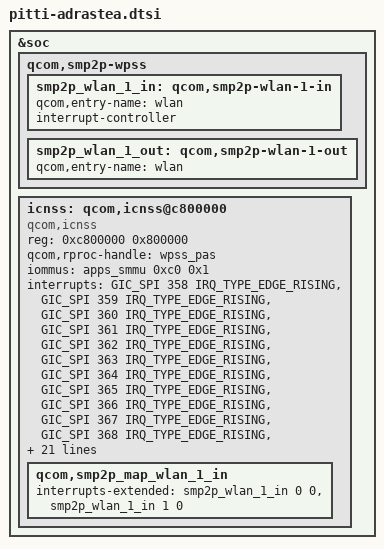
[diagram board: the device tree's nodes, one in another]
#include <dt-bindings/interrupt-controller/arm-gic.h>

&soc {
	qcom,smp2p-wpss {
		smp2p_wlan_1_in: qcom,smp2p-wlan-1-in {
			qcom,entry-name = "wlan";
			interrupt-controller;
			#interrupt-cells = <2>;
		};

		smp2p_wlan_1_out: qcom,smp2p-wlan-1-out {
			qcom,entry-name = "wlan";
			#qcom,smem-state-cells = <1>;
		};
	};


	icnss: qcom,icnss@c800000 {
		compatible = "qcom,icnss";
		reg = <0xc800000 0x800000>;
		reg-names = "membase";
		qcom,rproc-handle = <&wpss_pas>;
		iommus = <&apps_smmu 0xc0 0x1>;
		interrupts = <GIC_SPI 358 IRQ_TYPE_EDGE_RISING>,
			     <GIC_SPI 359 IRQ_TYPE_EDGE_RISING>,
			     <GIC_SPI 360 IRQ_TYPE_EDGE_RISING>,
			     <GIC_SPI 361 IRQ_TYPE_EDGE_RISING>,
			     <GIC_SPI 362 IRQ_TYPE_EDGE_RISING>,
			     <GIC_SPI 363 IRQ_TYPE_EDGE_RISING>,
			     <GIC_SPI 364 IRQ_TYPE_EDGE_RISING>,
			     <GIC_SPI 365 IRQ_TYPE_EDGE_RISING>,
			     <GIC_SPI 366 IRQ_TYPE_EDGE_RISING>,
			     <GIC_SPI 367 IRQ_TYPE_EDGE_RISING>,
			     <GIC_SPI 368 IRQ_TYPE_EDGE_RISING>,
			     <GIC_SPI 369 IRQ_TYPE_EDGE_RISING>;

		qcom,iommu-dma = "fastmap";
		qcom,iommu-faults = "stall-disable", "HUPCF", "non-fatal";
		qcom,iommu-dma-addr-pool = <0xb0000000 0x10000000>;
		qcom,iommu-geometry = <0xb0000000 0x10010000>;
		qcom,fw-prefix;
		qcom,wlan;
		wpss-support-enable;
		bdf-download-support;
		qcom,wlan-msa-fixed-region = <&wlan_msa_mem>;
		vdd-cx-mx-supply = <&L8A>;
		vdd-1.8-xo-supply = <&L12A>;
		vdd-1.3-rfa-supply = <&reg_1p3_rfa_fixed>;
		vdd-3.3-ch0-supply = <&L23A>;
		qcom,vdd-cx-mx-config = <0 0>;
		qcom,vdd-1.3-rfa-config = <0 0>; /* 1P3 rfa is controlled by eLDO, so no need to set voltage */
		qcom,vdd-3.3-ch0-config = <3000000 3312000 1>;

		qcom,smem-states = <&smp2p_wlan_1_out 0>;
		qcom,smem-state-names = "wlan-smp2p-out";

		qcom,smp2p_map_wlan_1_in {
			interrupts-extended = <&smp2p_wlan_1_in 0 0>,
					      <&smp2p_wlan_1_in 1 0>;
			interrupt-names = "qcom,smp2p-force-fatal-error",
					  "qcom,smp2p-early-crash-ind";
		};
	};
};
